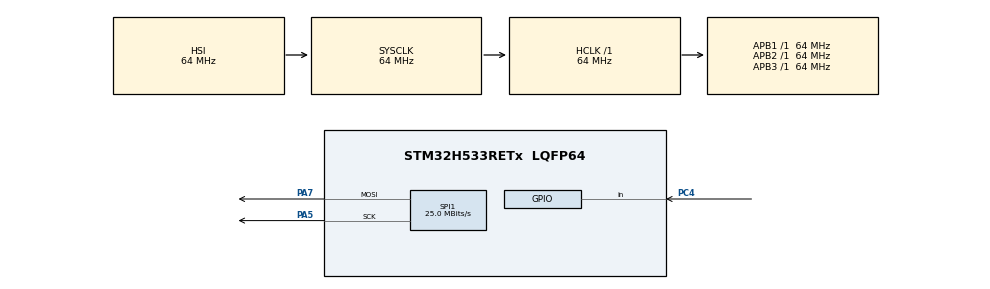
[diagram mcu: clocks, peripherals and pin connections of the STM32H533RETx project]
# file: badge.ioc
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BOOTPATH.BootPathName=LEGACY
BOOTPATH.UserSelectedBootPath=LEGACY
CORTEX_M33_NS.userName=CORTEX_M33
Mcu.Family=STM32H5
Mcu.Name=STM32H533RETx
Mcu.Package=LQFP64
NVIC.PriorityGroup=NVIC_PRIORITYGROUP_4
PA13(JTMS/SWDIO).GPIO_Label=SWDIO
PA13(JTMS/SWDIO).Signal=DEBUG_JTMS-SWDIO
PA14(JTCK/SWCLK).GPIO_Label=SWCLK
PA14(JTCK/SWCLK).Signal=DEBUG_JTCK-SWCLK
PA15(JTDI).GPIO_Label=JTDI
PA15(JTDI).Signal=DEBUG_JTDI
PA2.Signal=USART2_TX
PA3.Signal=USART2_RX
PA5.Mode=TX_Only_Simplex_Unidirect_Master
PA5.Signal=SPI1_SCK
PA7.Mode=TX_Only_Simplex_Unidirect_Master
PA7.Signal=SPI1_MOSI
PB3(JTDO/TRACESWO).GPIO_Label=SWO
PB3(JTDO/TRACESWO).Signal=DEBUG_JTDO-SWO
PC4.Signal=GPIO_Input
ProjectManager.HeapSize=0x200
ProjectManager.StackSize=0x400
ProjectManager.TargetToolchain=STM32CubeIDE
RCC.ADCFreq_Value=64000000
RCC.AHBFreq_Value=64000000
RCC.APB1Freq_Value=64000000
RCC.APB1TimFreq_Value=64000000
RCC.APB2Freq_Value=64000000
RCC.APB2TimFreq_Value=64000000
RCC.APB3Freq_Value=64000000
RCC.CSI_VALUE=4000000
RCC.CortexFreq_Value=64000000
RCC.EPOD_VALUE=4000000
RCC.HCLKFreq_Value=64000000
RCC.HSE_VALUE=25000000
RCC.HSI48_VALUE=48000000
RCC.HSIDiv=RCC_HSI_DIV1
RCC.HSI_VALUE=64000000
RCC.LSE_VALUE=32768
RCC.LSIRC_VALUE=32000
RCC.PLL1Q=4
RCC.PLLFRACN=0
RCC.PLLN=50
RCC.SYSCLKFreq_VALUE=64000000
RCC.USBFreq_Value=48000000
RCC.VCOOutputFreq_Value=200000000
SPI1.BaudRatePrescaler=SPI_BAUDRATEPRESCALER_2
SPI1.CalculateBaudRate=25.0 MBits/s
SPI1.DataSize=SPI_DATASIZE_8BIT
SPI1.Direction=SPI_DIRECTION_2LINES_TXONLY
SPI1.Mode=SPI_MODE_MASTER
SPI1.VirtualType=VM_MASTER
VP_BOOTPATH_VS_BOOTPATH.Mode=BP_Activate
VP_CORTEX_M33_NS_VS_Hclk.Mode=Hclk_Mode
VP_ICACHE_VS_ICACHE.Mode=DirectMappedCache
VP_MEMORYMAP_VS_MEMORYMAP.Mode=CurAppReg
VP_PWR_VS_DBSignals.Mode=DisableDeadBatterySignals
VP_PWR_VS_LPOM.Mode=PowerOptimisation
VP_PWR_VS_SECSignals.Mode=Security/Privilege
board=NUCLEO-H533RE

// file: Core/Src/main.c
/* USER CODE BEGIN Header */
/**
  ******************************************************************************
  * @file           : main.c
  * @brief          : Main program body
  ******************************************************************************
  * @attention
  *
  * Copyright (c) 2024 STMicroelectronics.
  * All rights reserved.
  *
  * This software is licensed under terms that can be found in the LICENSE file
  * in the root directory of this software component.
  * If no LICENSE file comes with this software, it is provided AS-IS.
  *
  ******************************************************************************
  */
/* USER CODE END Header */
#include "main.h"

/* USER CODE BEGIN Includes */
#include <string.h>
#include "LH128R.h"

/* USER CODE END Includes */

/* USER CODE BEGIN PD */
#define SQ_SIZE 240
/* USER CODE END PD */

SPI_HandleTypeDef hspi1;

void SystemClock_Config(void);
static void MX_GPIO_Init(void);
static void MX_ICACHE_Init(void);
static void MX_SPI1_Init(void);

/* USER CODE BEGIN 0 */
int16_t max(int16_t a, int16_t b)
{
	if(a > b)
	{
		return a;
	}
	else
	{
		return b;
	}
}

/* USER CODE END 0 */

int main(void)
{

  /* MCU Configuration--------------------------------------------------------*/

  /* Reset of all peripherals, Initializes the Flash interface and the Systick. */
  HAL_Init();

  /* Configure the system clock */
  SystemClock_Config();

  /* Initialize all configured peripherals */
  MX_GPIO_Init();
  MX_ICACHE_Init();
  MX_SPI1_Init();

  /* Infinite loop */
  /* USER CODE BEGIN WHILE */

  LH128R_init(&hspi1, GPIOA, GPIO_PIN_8, GPIOC, GPIO_PIN_7, GPIOC, GPIO_PIN_6);

  uint8_t pixel_data[240*240*3];

  LH128R_set_area(0, 0, 240, 240);
  memset(pixel_data, 255, sizeof(pixel_data));
  LH128R_write_to_area(pixel_data, sizeof(pixel_data)/4);
  LH128R_write_to_area(pixel_data+(sizeof(pixel_data)/4), sizeof(pixel_data)/4);
  LH128R_write_to_area(pixel_data+(sizeof(pixel_data)/2), sizeof(pixel_data)/4);
  LH128R_write_to_area(pixel_data+(sizeof(pixel_data)/4*3), sizeof(pixel_data)/4);

  while(1)
  {
	  for(int radius = 0; radius < 300; radius += 4)
	  {
		  int thickness = 3;  // Thickness of the circle line
		  int outerRadiusSquared = (radius + thickness) * (radius + thickness);
		  int innerRadiusSquared = (radius - thickness) * (radius - thickness);

		  for (int y = 0; y < 240; y++)
		  {

			  int dy = y - 120;
			  for (int x = 0; x < 240; x++)
			  {
				  int dx = x - 120;
				  int distSquared = dx * dx + dy * dy;

				  // Calculate the index in the pixel data array
				  int idx = (y * 240 + x) * 3;

				  // Check if the pixel is within the ring (circle with thickness)
				  if ((distSquared >= innerRadiusSquared) && (distSquared <= outerRadiusSquared)) {
					  // Set the pixel to white
					  pixel_data[idx] = 255;     // Red
					  pixel_data[idx + 1] = 255; // Green
					  pixel_data[idx + 2] = 255; // Blue
				  }
				  else
				  {
					  pixel_data[idx] = 0;     // Red
					  pixel_data[idx + 1] = 0; // Green
					  pixel_data[idx + 2] = 0; // Blue
				  }
			  }
		  }

		  LH128R_set_area(0, 0, 240-1, 240-1);
		  LH128R_write_to_area(pixel_data, sizeof(pixel_data)/4);
		  LH128R_write_to_area(pixel_data+(sizeof(pixel_data)/4), sizeof(pixel_data)/4);
		  LH128R_write_to_area(pixel_data+(sizeof(pixel_data)/2), sizeof(pixel_data)/4);
		  LH128R_write_to_area(pixel_data+(sizeof(pixel_data)/4*3), sizeof(pixel_data)/4);

	  }
  }

  /* MAX FRAME SPEED TEST */
//  uint8_t pixel_data1[120*120*3];
//  memset(pixel_data1, 255, sizeof(pixel_data1));
//  uint8_t pixel_data[120*120*3];
//  memset(pixel_data, 0, sizeof(pixel_data));
//
//
//  //LH128R_set_and_write_to_area(100, 100, 150, 150, pixel_data);
//  uint8_t cycle = 1;
//  while(1)
//  {
//
//	  LH128R_set_area(0, 0, SQ_SIZE-1, SQ_SIZE-1);
//	  if(cycle)
//	  {
//		  LH128R_write_to_area(pixel_data1, sizeof(pixel_data1));
//		  LH128R_write_to_area(pixel_data1, sizeof(pixel_data1));
//		  LH128R_write_to_area(pixel_data1, sizeof(pixel_data1));
//		  LH128R_write_to_area(pixel_data1, sizeof(pixel_data1));
//		  //memset(pixel_data, 0, sizeof(pixel_data));
//
//	  }
//	  else
//	  {
//		  LH128R_write_to_area(pixel_data, sizeof(pixel_data));
//		  LH128R_write_to_area(pixel_data, sizeof(pixel_data));
//		  LH128R_write_to_area(pixel_data, sizeof(pixel_data));
//		  LH128R_write_to_area(pixel_data, sizeof(pixel_data));
//		  //memset(pixel_data, 255, sizeof(pixel_data));
//	  }
//	  cycle = !cycle;
//	  //HAL_Delay(500);
//
//  }

  while (1)
  {

    /* USER CODE END WHILE */

  }
}

void SystemClock_Config(void)
{
  RCC_OscInitTypeDef RCC_OscInitStruct = {0};
  RCC_ClkInitTypeDef RCC_ClkInitStruct = {0};

  /** Configure the main internal regulator output voltage
  */
  __HAL_PWR_VOLTAGESCALING_CONFIG(PWR_REGULATOR_VOLTAGE_SCALE3);

  while(!__HAL_PWR_GET_FLAG(PWR_FLAG_VOSRDY)) {}

  /** Initializes the RCC Oscillators according to the specified parameters
  * in the RCC_OscInitTypeDef structure.
  */
  RCC_OscInitStruct.OscillatorType = RCC_OSCILLATORTYPE_HSI|RCC_OSCILLATORTYPE_CSI;
  RCC_OscInitStruct.HSIState = RCC_HSI_ON;
  RCC_OscInitStruct.HSIDiv = RCC_HSI_DIV1;
  RCC_OscInitStruct.HSICalibrationValue = RCC_HSICALIBRATION_DEFAULT;
  RCC_OscInitStruct.CSIState = RCC_CSI_ON;
  RCC_OscInitStruct.CSICalibrationValue = RCC_CSICALIBRATION_DEFAULT;
  RCC_OscInitStruct.PLL.PLLState = RCC_PLL_ON;
  RCC_OscInitStruct.PLL.PLLSource = RCC_PLL1_SOURCE_CSI;
  RCC_OscInitStruct.PLL.PLLM = 1;
  RCC_OscInitStruct.PLL.PLLN = 50;
  RCC_OscInitStruct.PLL.PLLP = 2;
  RCC_OscInitStruct.PLL.PLLQ = 4;
  RCC_OscInitStruct.PLL.PLLR = 2;
  RCC_OscInitStruct.PLL.PLLRGE = RCC_PLL1_VCIRANGE_2;
  RCC_OscInitStruct.PLL.PLLVCOSEL = RCC_PLL1_VCORANGE_WIDE;
  RCC_OscInitStruct.PLL.PLLFRACN = 0;
  if (HAL_RCC_OscConfig(&RCC_OscInitStruct) != HAL_OK)
  {
    Error_Handler();
  }

  /** Initializes the CPU, AHB and APB buses clocks
  */
  RCC_ClkInitStruct.ClockType = RCC_CLOCKTYPE_HCLK|RCC_CLOCKTYPE_SYSCLK
                              |RCC_CLOCKTYPE_PCLK1|RCC_CLOCKTYPE_PCLK2
                              |RCC_CLOCKTYPE_PCLK3;
  RCC_ClkInitStruct.SYSCLKSource = RCC_SYSCLKSOURCE_HSI;
  RCC_ClkInitStruct.AHBCLKDivider = RCC_SYSCLK_DIV1;
  RCC_ClkInitStruct.APB1CLKDivider = RCC_HCLK_DIV1;
  RCC_ClkInitStruct.APB2CLKDivider = RCC_HCLK_DIV1;
  RCC_ClkInitStruct.APB3CLKDivider = RCC_HCLK_DIV1;

  if (HAL_RCC_ClockConfig(&RCC_ClkInitStruct, FLASH_LATENCY_3) != HAL_OK)
  {
    Error_Handler();
  }

  /** Configure the programming delay
  */
  __HAL_FLASH_SET_PROGRAM_DELAY(FLASH_PROGRAMMING_DELAY_1);
}

static void MX_ICACHE_Init(void)
{

  /** Enable instruction cache in 1-way (direct mapped cache)
  */
  if (HAL_ICACHE_ConfigAssociativityMode(ICACHE_1WAY) != HAL_OK)
  {
    Error_Handler();
  }
  if (HAL_ICACHE_Enable() != HAL_OK)
  {
    Error_Handler();
  }

}

static void MX_SPI1_Init(void)
{

  /* SPI1 parameter configuration*/
  hspi1.Instance = SPI1;
  hspi1.Init.Mode = SPI_MODE_MASTER;
  hspi1.Init.Direction = SPI_DIRECTION_2LINES_TXONLY;
  hspi1.Init.DataSize = SPI_DATASIZE_8BIT;
  hspi1.Init.CLKPolarity = SPI_POLARITY_LOW;
  hspi1.Init.CLKPhase = SPI_PHASE_1EDGE;
  hspi1.Init.NSS = SPI_NSS_SOFT;
  hspi1.Init.BaudRatePrescaler = SPI_BAUDRATEPRESCALER_2;
  hspi1.Init.FirstBit = SPI_FIRSTBIT_MSB;
  hspi1.Init.TIMode = SPI_TIMODE_DISABLE;
  hspi1.Init.CRCCalculation = SPI_CRCCALCULATION_DISABLE;
  hspi1.Init.CRCPolynomial = 0x7;
  hspi1.Init.NSSPMode = SPI_NSS_PULSE_ENABLE;
  hspi1.Init.NSSPolarity = SPI_NSS_POLARITY_LOW;
  hspi1.Init.FifoThreshold = SPI_FIFO_THRESHOLD_01DATA;
  hspi1.Init.MasterSSIdleness = SPI_MASTER_SS_IDLENESS_00CYCLE;
  hspi1.Init.MasterInterDataIdleness = SPI_MASTER_INTERDATA_IDLENESS_00CYCLE;
  hspi1.Init.MasterReceiverAutoSusp = SPI_MASTER_RX_AUTOSUSP_DISABLE;
  hspi1.Init.MasterKeepIOState = SPI_MASTER_KEEP_IO_STATE_DISABLE;
  hspi1.Init.IOSwap = SPI_IO_SWAP_DISABLE;
  hspi1.Init.ReadyMasterManagement = SPI_RDY_MASTER_MANAGEMENT_INTERNALLY;
  hspi1.Init.ReadyPolarity = SPI_RDY_POLARITY_HIGH;
  if (HAL_SPI_Init(&hspi1) != HAL_OK)
  {
    Error_Handler();
  }

}

static void MX_GPIO_Init(void)
{
  GPIO_InitTypeDef GPIO_InitStruct = {0};

  /* GPIO Ports Clock Enable */
  __HAL_RCC_GPIOA_CLK_ENABLE();
  __HAL_RCC_GPIOC_CLK_ENABLE();
  __HAL_RCC_GPIOB_CLK_ENABLE();

  /*Configure GPIO pins : PA2 PA3 */
  GPIO_InitStruct.Pin = GPIO_PIN_2|GPIO_PIN_3;
  GPIO_InitStruct.Mode = GPIO_MODE_AF_PP;
  GPIO_InitStruct.Pull = GPIO_NOPULL;
  GPIO_InitStruct.Speed = GPIO_SPEED_FREQ_LOW;
  GPIO_InitStruct.Alternate = GPIO_AF7_USART2;
  HAL_GPIO_Init(GPIOA, &GPIO_InitStruct);

  /*Configure GPIO pin : PC4 */
  GPIO_InitStruct.Pin = GPIO_PIN_4;
  GPIO_InitStruct.Mode = GPIO_MODE_INPUT;
  GPIO_InitStruct.Pull = GPIO_NOPULL;
  HAL_GPIO_Init(GPIOC, &GPIO_InitStruct);

}

void Error_Handler(void)
{
  __disable_irq();
  while (1)
  {
  }
}
